# STM32L4x3 register map
File version: 1.3
CPU: CM4 r1p0, little endian, no MPU, no FPU, 3 interrupt priority bits
Registers are 32-bit, read-write, reset 0x0 unless marked. A register's access mark holds for its fields unless they carry their own. Offsets are from the block's base; [hi:lo] are bit positions; {n}, {i} and the like mark numbered series.

## ADC — Analog-to-Digital Converter
Base 0x50040000
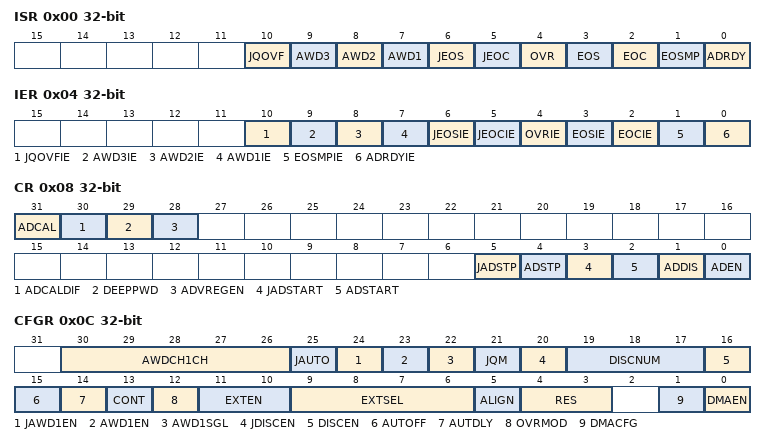
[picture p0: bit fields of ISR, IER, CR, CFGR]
0x00 ISR — interrupt and status register
  [10] JQOVF, [9] AWD3, [8] AWD2, [7] AWD1, [6] JEOS, [5] JEOC, [4] OVR, [3] EOS, [2] EOC, [1] EOSMP, [0] ADRDY
0x04 IER — interrupt enable register
  [10] JQOVFIE, [9] AWD3IE, [8] AWD2IE, [7] AWD1IE, [6] JEOSIE, [5] JEOCIE, [4] OVRIE, [3] EOSIE, [2] EOCIE, [1] EOSMPIE, [0] ADRDYIE
0x08 CR — control register
  [31] ADCAL, [30] ADCALDIF, [29] DEEPPWD, [28] ADVREGEN, [5] JADSTP, [4] ADSTP, [3] JADSTART, [2] ADSTART, [1] ADDIS, [0] ADEN
0x0C CFGR — configuration register
  [30:26] AWDCH1CH, [25] JAUTO, [24] JAWD1EN, [23] AWD1EN, [22] AWD1SGL, [21] JQM, [20] JDISCEN, [19:17] DISCNUM, [16] DISCEN, [15] AUTOFF, [14] AUTDLY, [13] CONT, [12] OVRMOD, [11:10] EXTEN, [9:6] EXTSEL, [5] ALIGN, [4:3] RES, [1] DMACFG, [0] DMAEN
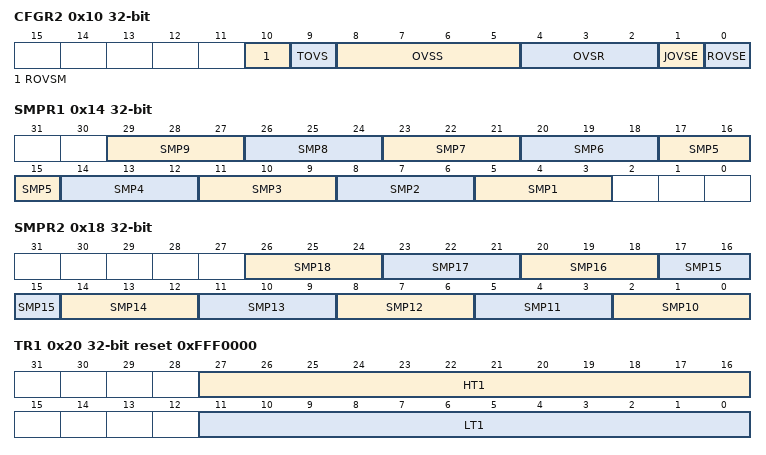
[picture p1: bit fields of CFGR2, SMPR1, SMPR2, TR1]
0x10 CFGR2 — configuration register
  [10] ROVSM — EXTEN
  [9] TOVS — EXTSEL
  [8:5] OVSS — ALIGN
  [4:2] OVSR — RES
  [1] JOVSE — DMACFG
  [0] ROVSE — DMAEN
0x14 SMPR1 — sample time register 1
  [3n+2:3n] SMP{n} (n=1..9)
0x18 SMPR2 — sample time register 2
  [3n-28:3n-30] SMP{n} (n=10..18)
0x20 TR1 reset 0xFFF0000 — watchdog threshold register 1
  [27:16] HT1, [11:0] LT1
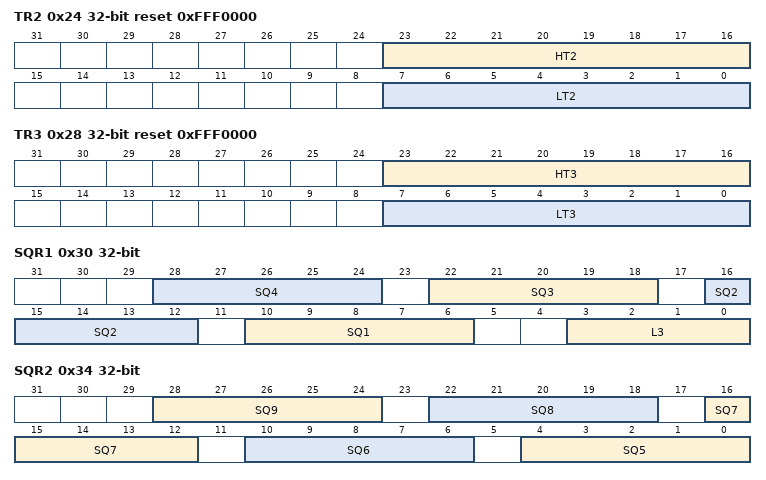
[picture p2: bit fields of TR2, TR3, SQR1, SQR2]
0x24 TR2 reset 0xFFF0000 — watchdog threshold register
  [23:16] HT2, [7:0] LT2
0x28 TR3 reset 0xFFF0000 — watchdog threshold register 3
  [23:16] HT3, [7:0] LT3
0x30 SQR1 — regular sequence register 1
  [6n+4:6n] SQ{n} (n=1..4), [3:0] L3
0x34 SQR2 — regular sequence register 2
  [6n-26:6n-30] SQ{n} (n=5..9)
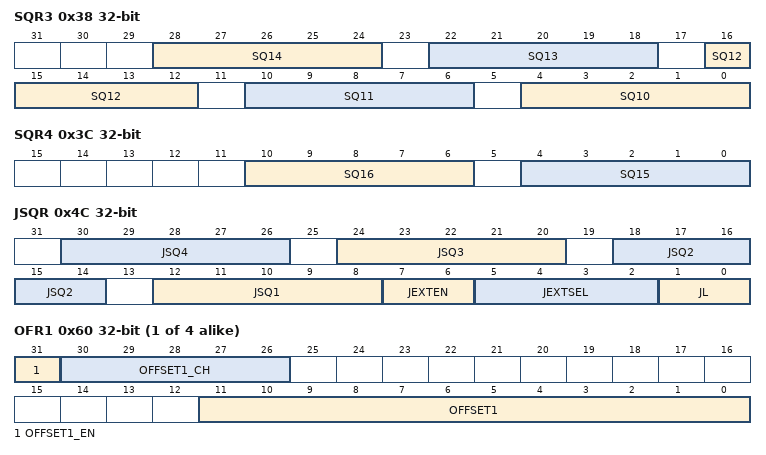
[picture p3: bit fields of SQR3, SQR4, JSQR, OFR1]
0x38 SQR3 — regular sequence register 3
  [6n-56:6n-60] SQ{n} (n=10..14)
0x3C SQR4 — regular sequence register 4
  [10:6] SQ16, [4:0] SQ15
0x40 DR ro — regular Data Register
  [15:0] regularDATA
0x4C JSQR — injected sequence register
  [6n+6:6n+2] JSQ{n} (n=1..4), [7:6] JEXTEN, [5:2] JEXTSEL, [1:0] JL
{0x5C+4i} OFR{i} (i=1..4) — offset register {i}
  [31] OFFSET{i}_EN, [30:26] OFFSET{i}_CH, [11:0] OFFSET{i}
{0x7C+4i} JDR{i} ro (i=1..4) — injected data register {i}
  [15:0] JDATA{i}
0xA0 AWD2CR — Analog Watchdog 2 Configuration Register
  [18:1] AWD2CH
0xA4 AWD3CR — Analog Watchdog 3 Configuration Register
  [18:1] AWD3CH
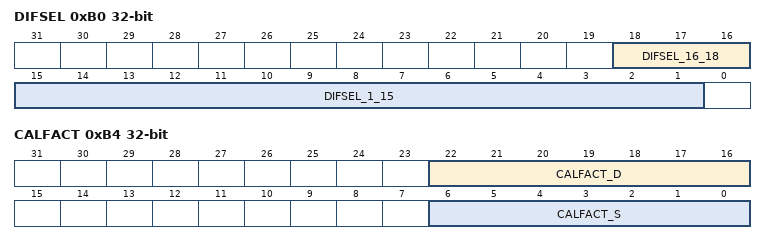
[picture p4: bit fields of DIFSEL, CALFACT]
0xB0 DIFSEL access per field — Differential Mode Selection Register 2
  [18:16] DIFSEL_16_18 ro — Differential mode for channels 18 to 16
  [15:1] DIFSEL_1_15 rw — Differential mode for channels 15 to 1
0xB4 CALFACT — Calibration Factors
  [22:16] CALFACT_D, [6:0] CALFACT_S

## GPIOA — General-purpose I/Os
Base 0x48000000
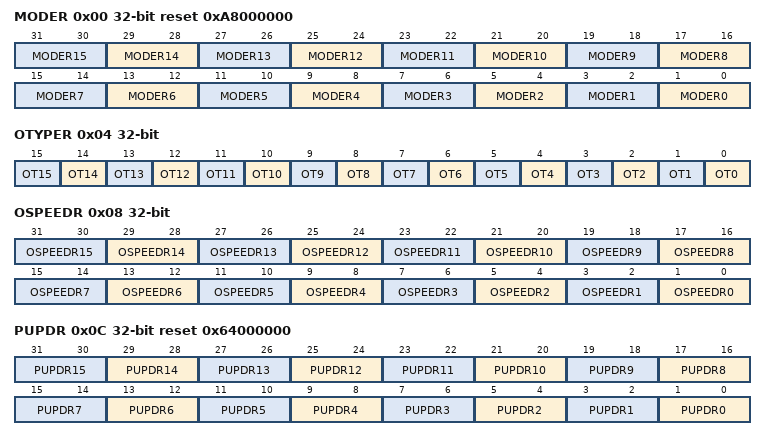
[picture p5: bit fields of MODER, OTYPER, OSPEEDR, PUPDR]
0x00 MODER reset 0xA8000000 — GPIO port mode register
  [2n+1:2n] MODER{n} (n=0..15) — Port x configuration bits (y = 0..15)
0x04 OTYPER — GPIO port output type register
  [n] OT{n} (n=0..15) — Port x configuration bits (y = 0..15)
0x08 OSPEEDR — GPIO port output speed register
  [2n+1:2n] OSPEEDR{n} (n=0..15) — Port x configuration bits (y = 0..15)
0x0C PUPDR reset 0x64000000 — GPIO port pull-up/pull-down register
  [2n+1:2n] PUPDR{n} (n=0..15) — Port x configuration bits (y = 0..15)
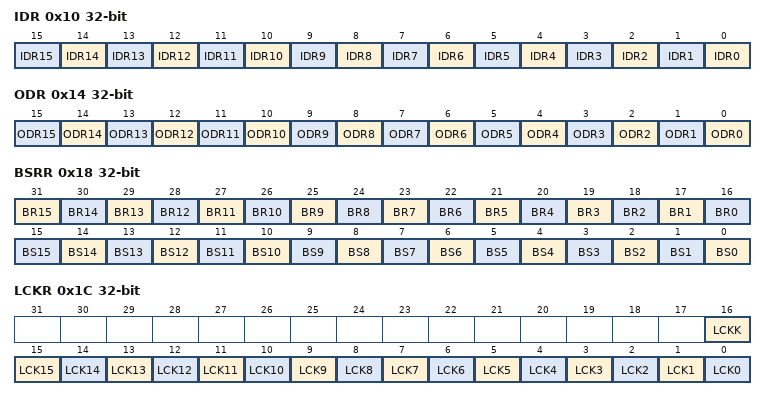
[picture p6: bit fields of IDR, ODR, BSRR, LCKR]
0x10 IDR ro — GPIO port input data register
  [n] IDR{n} (n=0..15) — Port input data (y = 0..15)
0x14 ODR — GPIO port output data register
  [n] ODR{n} (n=0..15) — Port output data (y = 0..15)
0x18 BSRR wo — GPIO port bit set/reset register
  [n+16] BR{n} (n=1..15) — Port x reset bit y (y = 0..15)
  [16] BR0 — Port x set bit y (y= 0..15)
  [n] BS{n} (n=0..15) — Port x set bit y (y= 0..15)
0x1C LCKR — GPIO port configuration lock register
  [16] LCKK — Port x lock bit y (y= 0..15)
  [n] LCK{n} (n=0..15) — Port x lock bit y (y= 0..15)
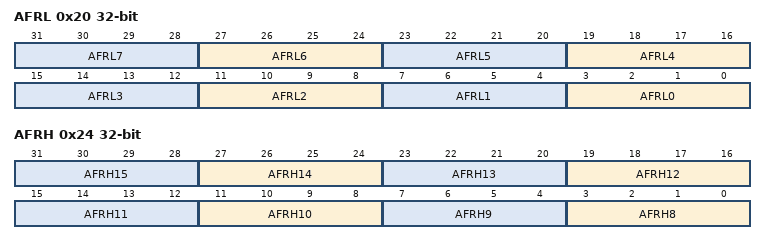
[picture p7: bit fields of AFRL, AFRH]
0x20 AFRL — GPIO alternate function low register
  [4n+3:4n] AFRL{n} (n=0..7) — Alternate function selection for port x bit y (y = 0..7)
0x24 AFRH — GPIO alternate function high register
  [4n-29:4n-32] AFRH{n} (n=8..15) — Alternate function selection for port x bit y (y = 8..15)

## GPIOB — General-purpose I/Os
Base 0x48000400
Registers as GPIOA; these are added or differ:
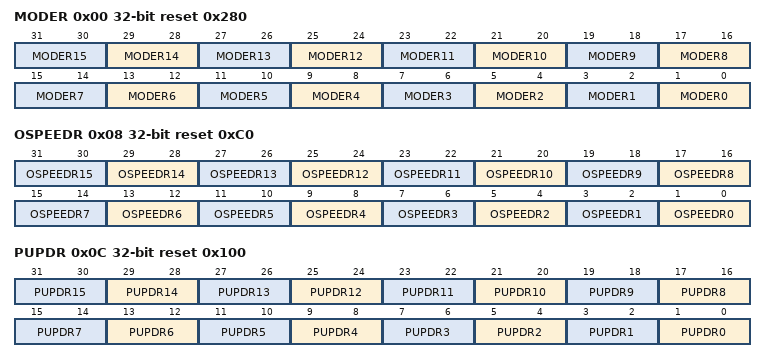
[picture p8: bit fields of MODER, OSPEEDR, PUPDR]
0x00 MODER reset 0x280 — GPIO port mode register
  [2n+1:2n] MODER{n} (n=0..15) — Port x configuration bits (y = 0..15)
0x08 OSPEEDR reset 0xC0 — GPIO port output speed register
  [2n+1:2n] OSPEEDR{n} (n=0..15) — Port x configuration bits (y = 0..15)
0x0C PUPDR reset 0x100 — GPIO port pull-up/pull-down register
  [2n+1:2n] PUPDR{n} (n=0..15) — Port x configuration bits (y = 0..15)

## GPIOC — General-purpose I/Os
Base 0x48000800
Same registers: GPIOD 0x48000C00, GPIOE 0x48001000, GPIOH 0x48001C00
Registers as GPIOA; these are added or differ:
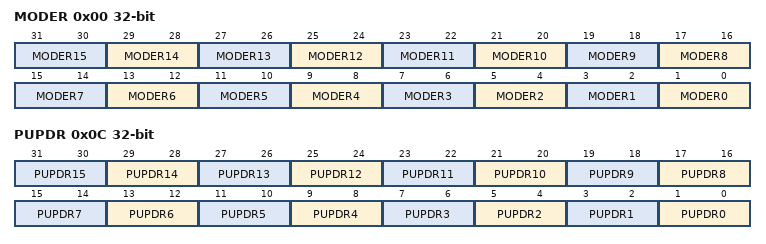
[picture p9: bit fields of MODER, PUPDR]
0x00 MODER — GPIO port mode register
  [2n+1:2n] MODER{n} (n=0..15) — Port x configuration bits (y = 0..15)
0x0C PUPDR — GPIO port pull-up/pull-down register
  [2n+1:2n] PUPDR{n} (n=0..15) — Port x configuration bits (y = 0..15)
